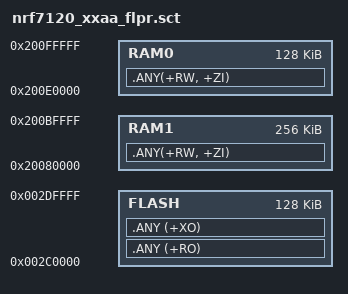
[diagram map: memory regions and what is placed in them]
LOAD 0x002C0000 0x00020000
{
    FLASH 0x002C0000 0x00020000
    {
    
        .ANY (+RO)
        .ANY (+XO)
    }

    RAM0 0x200E0000 0x00020000
    {
    .ANY(+RW, +ZI) ; RW data and ZI data
    }

    RAM1 0x20080000 0x00040000
    {
    .ANY(+RW, +ZI) ; RW data and ZI data
    }

}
